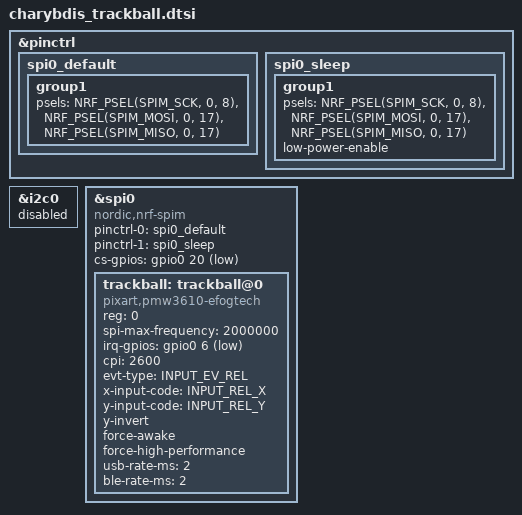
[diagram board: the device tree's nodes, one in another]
/*
 * Charybdis on-board trackball on the right half.
 * Pins are from charlesmst/charybdis-wireless (SPI0 SCK P0.8, MOSI/MISO P0.17,
 * CS gpio0 20, IRQ gpio0 6), but the driver is the SAME efogtech PMW3610 driver
 * roBa uses (pixart,pmw3610-efogtech) rather than the inorichi pixart,pmw3610.
 *
 * Orientation is handled downstream by the hsgw sensor_rotation input processor
 * (true rotation, 5deg steps) in charybdis_esb_right.overlay — NOT by the
 * driver's xy-swap/x-invert register bits, which are a reflection (mirror) and
 * make diagonals feel wrong. Left raw here.
 */

&pinctrl {
    spi0_default: spi0_default {
        group1 {
            psels = <NRF_PSEL(SPIM_SCK, 0, 8)>,
                <NRF_PSEL(SPIM_MOSI, 0, 17)>,
                <NRF_PSEL(SPIM_MISO, 0, 17)>;
        };
    };

    spi0_sleep: spi0_sleep {
        group1 {
            psels = <NRF_PSEL(SPIM_SCK, 0, 8)>,
                <NRF_PSEL(SPIM_MOSI, 0, 17)>,
                <NRF_PSEL(SPIM_MISO, 0, 17)>;
            low-power-enable;
        };
    };
};

/* SPI0 and i2c0 (TWI0) share peripheral instance 0 on the nRF52840; the
 * nice_nano enables i2c0 by default, so free the instance for the trackball. */
&i2c0 { status = "disabled"; };

&spi0 {
    compatible = "nordic,nrf-spim";
    status = "disabled";

    trackball: trackball@0 {
        compatible = "pixart,pmw3610-efogtech";
        status = "disabled";
        reg = <0>;
        spi-max-frequency = <2000000>;
    };
};

&spi0 {
    status = "okay";
    pinctrl-0 = <&spi0_default>;
    pinctrl-1 = <&spi0_sleep>;
    pinctrl-names = "default", "sleep";
    cs-gpios = <&gpio0 20 GPIO_ACTIVE_LOW>;
};

#include <zephyr/dt-bindings/input/input-event-codes.h>

&trackball {
    status = "okay";
    irq-gpios = <&gpio0 6 (GPIO_ACTIVE_LOW | GPIO_PULL_UP)>;
    cpi = <2600>;
    evt-type = <INPUT_EV_REL>;
    x-input-code = <INPUT_REL_X>;
    y-input-code = <INPUT_REL_Y>;
    /* Single-axis flip for the trackball's mirrored mounting (the rotation
     * processor handles angle; it can't do a reflection). */
    y-invert;
    force-awake;
    force-high-performance;
    usb-rate-ms = <2>;
    ble-rate-ms = <2>;
};
